# ATmega169PA device description
Architecture: AVR8; Family: megaAVR
Registers are 8-bit, access not given, no defined reset value unless marked. A register's access mark holds for its fields unless they carry their own. Offsets are from the block's base; [hi:lo] are bit positions.

## LOCKBIT — Lockbits
Instances: LOCKBIT 0 in lockbits
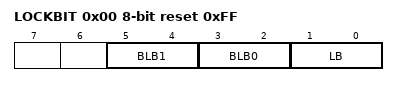
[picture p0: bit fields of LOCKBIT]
0x00 LOCKBIT reset 0xFF
  [5:4] BLB1 — Boot Loader Protection Mode
    0=LPM_SPM_DISABLE (LPM and SPM prohibited in Boot Section); 1=LPM_DISABLE (LPM prohibited in Boot Section); 2=SPM_DISABLE (SPM prohibited in Boot Section); 3=NO_LOCK (No lock on SPM and LPM in Boot Section)
  [3:2] BLB0 — Boot Loader Protection Mode
    0=LPM_SPM_DISABLE (LPM and SPM prohibited in Application Section); 1=LPM_DISABLE (LPM prohibited in Application Section); 2=SPM_DISABLE (SPM prohibited in Application Section); 3=NO_LOCK (No lock on SPM and LPM in Application Section)
  [1:0] LB — Memory Lock
    0=PROG_VER_DISABLED (Further programming and verification disabled); 2=PROG_DISABLED (Further programming disabled); 3=NO_LOCK (No memory lock features enabled)

## TC0 (TC8 module) — Timer/Counter, 8-bit
Instances: TC0 0x00
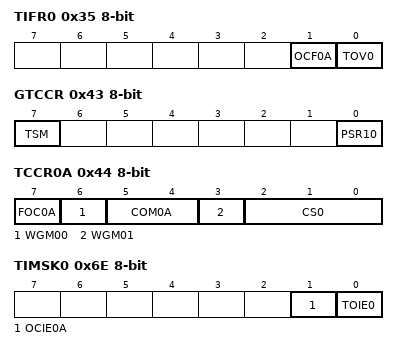
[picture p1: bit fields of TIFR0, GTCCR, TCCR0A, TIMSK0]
0x35 TIFR0 — Timer/Counter0 Interrupt Flag register
  [1] OCF0A — Timer/Counter0 Output Compare Flag 0
  [0] TOV0 — Timer/Counter0 Overflow Flag
0x43 GTCCR — General Timer/Control Register
  [7] TSM — Timer/Counter Synchronization Mode
  [0] PSR10 — Prescaler Reset Timer/Counter1 and Timer/Counter0
0x44 TCCR0A — Timer/Counter0 Control Register
  [7] FOC0A — Force Output Compare
  [6] WGM00 — Waveform Generation Mode 0
    0=Normal; 2=PWM, Phase Correct; 1=CTC; 3=Fast PWM
  [5:4] COM0A — Compare Match Output Modes
  [3] WGM01 — Waveform Generation Mode 1
  [2:0] CS0 — Clock Selects
    0=No Clock Source (Stopped); 1=Running, No Prescaling; 2=Running, CLK/8; 3=Running, CLK/64; 4=Running, CLK/256; 5=Running, CLK/1024; 6=Running, ExtClk Tx Falling Edge; 7=Running, ExtClk Tx Rising Edge
0x46 TCNT0 — Timer/Counter0
  [7:0] TCNT0 — Timer/Counter0 bits
0x47 OCR0A — Timer/Counter0 Output Compare Register
  [7:0] OCR0A — Timer/Counter0 Output Compare A
0x6E TIMSK0 — Timer/Counter0 Interrupt Mask Register
  [1] OCIE0A — Timer/Counter0 Output Compare Match Interrupt Enable
  [0] TOIE0 — Timer/Counter0 Overflow Interrupt Enable

## TC1 (TC16 module) — Timer/Counter, 16-bit
Instances: TC1 0x00
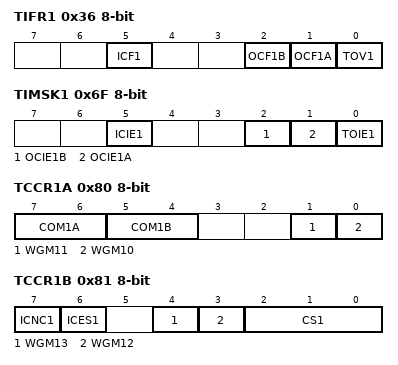
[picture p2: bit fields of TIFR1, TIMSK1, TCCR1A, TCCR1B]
0x36 TIFR1 — Timer/Counter1 Interrupt Flag register
  [5] ICF1 — Input Capture Flag 1
  [2] OCF1B — Output Compare Flag 1B
  [1] OCF1A — Output Compare Flag 1A
  [0] TOV1 — Timer/Counter1 Overflow Flag
0x6F TIMSK1 — Timer/Counter1 Interrupt Mask Register
  [5] ICIE1 — Timer/Counter1 Input Capture Interrupt Enable
  [2] OCIE1B — Timer/Counter1 Output Compare B Match Interrupt Enable
  [1] OCIE1A — Timer/Counter1 Output Compare A Match Interrupt Enable
  [0] TOIE1 — Timer/Counter1 Overflow Interrupt Enable
0x80 TCCR1A — Timer/Counter1 Control Register A
  [7:6] COM1A — Compare Output Mode 1A, bits
  [5:4] COM1B — Compare Output Mode 1B, bits
  [1] WGM11 — Waveform Generation Mode
  [0] WGM10 — Waveform Generation Mode
0x81 TCCR1B — Timer/Counter1 Control Register B
  [7] ICNC1 — Input Capture 1 Noise Canceler
  [6] ICES1 — Input Capture 1 Edge Select
  [4] WGM13 (bit 2 of the value upward) — Waveform Generation Mode
  [3] WGM12 (bit 2 of the value upward) — Waveform Generation Mode
  [2:0] CS1 — Prescaler source of Timer/Counter 1
    0=No Clock Source (Stopped); 1=Running, No Prescaling; 2=Running, CLK/8; 3=Running, CLK/64; 4=Running, CLK/256; 5=Running, CLK/1024; 6=Running, ExtClk Tx Falling Edge; 7=Running, ExtClk Tx Rising Edge
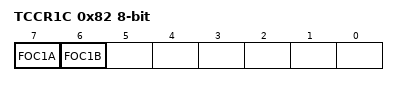
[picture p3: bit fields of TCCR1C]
0x82 TCCR1C — Timer/Counter 1 Control Register C
  [7] FOC1A — Force Output Compare 1A
  [6] FOC1B — Force Output Compare 1B
0x84 TCNT1 16-bit — Timer/Counter1 Bytes
  [15:0] TCNT1 — Timer/Counter1 bits
0x86 ICR1 16-bit — Timer/Counter1 Input Capture Register Bytes
  [15:0] ICR1 — Timer/Counter1 Input Capture
0x88 OCR1A 16-bit — Timer/Counter1 Output Compare Register A Bytes
  [15:0] OCR1A — Timer/Counter1 Output Compare A
0x8A OCR1B 16-bit — Timer/Counter1 Output Compare Register B Bytes
  [15:0] OCR1B — Timer/Counter1 Output Compare B
